VERSION "HIPBNYYYYYYYYYYYYYYYYYYYYYYYYYYYYYYYYYYYYY/4/%%%/4/'%**4YYY///"

NS_ :

BS_:

BU_: Photon3

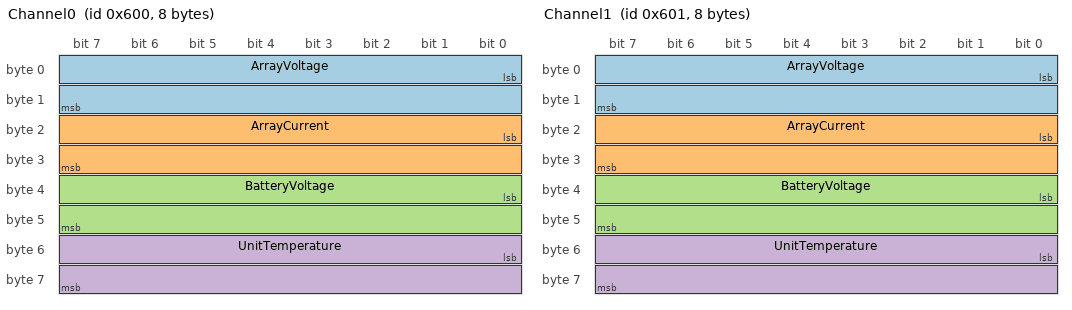
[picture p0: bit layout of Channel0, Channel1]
BO_ 1536 Channel0: 8 Photon3
 SG_ ArrayVoltage : 0|16@1+ (0.01,0) [0|0] "V" Vector__XXX
 SG_ ArrayCurrent : 16|16@1+ (0.001,0) [0|0] "A" Vector__XXX
 SG_ BatteryVoltage : 32|16@1+ (0.01,0) [0|0] "V" Vector__XXX
 SG_ UnitTemperature : 48|16@1+ (0.01,0) [0|0] "C" Vector__XXX

BO_ 1537 Channel1: 8 Photon3
 SG_ ArrayVoltage : 0|16@1+ (0.01,0) [0|0] "V" Vector__XXX
 SG_ ArrayCurrent : 16|16@1+ (0.001,0) [0|0] "A" Vector__XXX
 SG_ BatteryVoltage : 32|16@1+ (0.01,0) [0|0] "V" Vector__XXX
 SG_ UnitTemperature : 48|16@1+ (0.01,0) [0|0] "C" Vector__XXX
